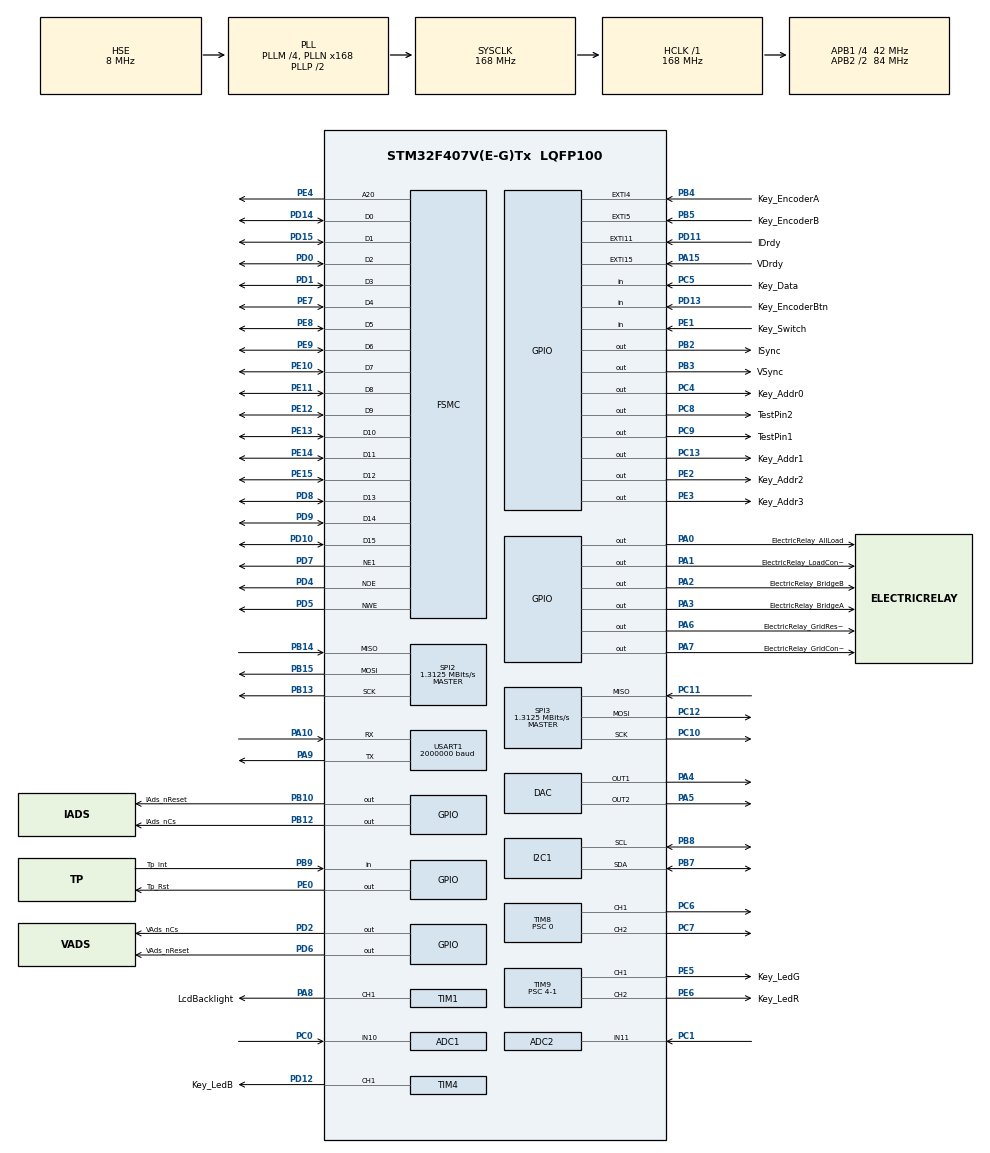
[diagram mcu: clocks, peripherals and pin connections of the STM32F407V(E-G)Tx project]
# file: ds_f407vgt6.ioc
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ADC1.Channel-5\#ChannelRegularConversion=ADC_CHANNEL_10
ADC1.ClockPrescaler=ADC_CLOCK_SYNC_PCLK_DIV8
ADC1.ContinuousConvMode=DISABLE
ADC1.DMAContinuousRequests=ENABLE
ADC1.EOCSelection=ADC_EOC_SEQ_CONV
ADC1.ExternalTrigConv=ADC_EXTERNALTRIGCONV_T2_TRGO
ADC1.NbrOfConversion=1
ADC1.NbrOfConversionFlag=1
ADC1.Rank-5\#ChannelRegularConversion=1
ADC1.SamplingTime-5\#ChannelRegularConversion=ADC_SAMPLETIME_480CYCLES
ADC1.ScanConvMode=DISABLE
ADC1.master=1
ADC2.Channel-1\#ChannelRegularConversion=ADC_CHANNEL_11
ADC2.ClockPrescaler=ADC_CLOCK_SYNC_PCLK_DIV8
ADC2.ContinuousConvMode=DISABLE
ADC2.DMAContinuousRequests=ENABLE
ADC2.EOCSelection=ADC_EOC_SEQ_CONV
ADC2.ExternalTrigConv=ADC_EXTERNALTRIGCONV_T2_TRGO
ADC2.NbrOfConversionFlag=1
ADC2.Rank-1\#ChannelRegularConversion=1
ADC2.SamplingTime-1\#ChannelRegularConversion=ADC_SAMPLETIME_480CYCLES
DAC.DAC_OutputBuffer=DAC_OUTPUTBUFFER_DISABLE
DAC.DAC_OutputBuffer2=DAC_OUTPUTBUFFER_DISABLE
Dma.ADC1.7.Direction=DMA_PERIPH_TO_MEMORY
Dma.ADC1.7.FIFOMode=DMA_FIFOMODE_DISABLE
Dma.ADC1.7.Instance=DMA2_Stream4
Dma.ADC1.7.MemDataAlignment=DMA_MDATAALIGN_HALFWORD
Dma.ADC1.7.MemInc=DMA_MINC_ENABLE
Dma.ADC1.7.Mode=DMA_CIRCULAR
Dma.ADC1.7.PeriphDataAlignment=DMA_PDATAALIGN_HALFWORD
Dma.ADC1.7.PeriphInc=DMA_PINC_DISABLE
Dma.ADC1.7.Priority=DMA_PRIORITY_HIGH
Dma.ADC2.8.Direction=DMA_PERIPH_TO_MEMORY
Dma.ADC2.8.FIFOMode=DMA_FIFOMODE_DISABLE
Dma.ADC2.8.Instance=DMA2_Stream3
Dma.ADC2.8.MemDataAlignment=DMA_MDATAALIGN_HALFWORD
Dma.ADC2.8.MemInc=DMA_MINC_ENABLE
Dma.ADC2.8.Mode=DMA_CIRCULAR
Dma.ADC2.8.PeriphDataAlignment=DMA_PDATAALIGN_HALFWORD
Dma.ADC2.8.PeriphInc=DMA_PINC_DISABLE
Dma.ADC2.8.Priority=DMA_PRIORITY_HIGH
Dma.MEMTOMEM.2.Direction=DMA_MEMORY_TO_MEMORY
Dma.MEMTOMEM.2.FIFOMode=DMA_FIFOMODE_ENABLE
Dma.MEMTOMEM.2.FIFOThreshold=DMA_FIFO_THRESHOLD_FULL
Dma.MEMTOMEM.2.Instance=DMA2_Stream1
Dma.MEMTOMEM.2.MemBurst=DMA_MBURST_SINGLE
Dma.MEMTOMEM.2.MemDataAlignment=DMA_MDATAALIGN_HALFWORD
Dma.MEMTOMEM.2.MemInc=DMA_MINC_DISABLE
Dma.MEMTOMEM.2.Mode=DMA_NORMAL
Dma.MEMTOMEM.2.PeriphBurst=DMA_PBURST_SINGLE
Dma.MEMTOMEM.2.PeriphDataAlignment=DMA_PDATAALIGN_HALFWORD
Dma.MEMTOMEM.2.PeriphInc=DMA_PINC_ENABLE
Dma.MEMTOMEM.2.Priority=DMA_PRIORITY_LOW
Dma.Request0=USART1_RX
Dma.Request1=USART1_TX
Dma.Request2=MEMTOMEM
Dma.Request3=SPI2_RX
Dma.Request4=SPI3_RX
Dma.Request5=SPI2_TX
Dma.Request6=SPI3_TX
Dma.Request7=ADC1
Dma.Request8=ADC2
Dma.SPI2_RX.3.Direction=DMA_PERIPH_TO_MEMORY
Dma.SPI2_RX.3.FIFOMode=DMA_FIFOMODE_DISABLE
Dma.SPI2_RX.3.Instance=DMA1_Stream3
Dma.SPI2_RX.3.MemDataAlignment=DMA_MDATAALIGN_BYTE
Dma.SPI2_RX.3.MemInc=DMA_MINC_ENABLE
Dma.SPI2_RX.3.Mode=DMA_NORMAL
Dma.SPI2_RX.3.PeriphDataAlignment=DMA_PDATAALIGN_BYTE
Dma.SPI2_RX.3.PeriphInc=DMA_PINC_DISABLE
Dma.SPI2_RX.3.Priority=DMA_PRIORITY_LOW
Dma.SPI2_TX.5.Direction=DMA_MEMORY_TO_PERIPH
Dma.SPI2_TX.5.FIFOMode=DMA_FIFOMODE_DISABLE
Dma.SPI2_TX.5.Instance=DMA1_Stream4
Dma.SPI2_TX.5.MemDataAlignment=DMA_MDATAALIGN_BYTE
Dma.SPI2_TX.5.MemInc=DMA_MINC_ENABLE
Dma.SPI2_TX.5.Mode=DMA_NORMAL
Dma.SPI2_TX.5.PeriphDataAlignment=DMA_PDATAALIGN_BYTE
Dma.SPI2_TX.5.PeriphInc=DMA_PINC_DISABLE
Dma.SPI2_TX.5.Priority=DMA_PRIORITY_LOW
Dma.SPI3_RX.4.Direction=DMA_PERIPH_TO_MEMORY
Dma.SPI3_RX.4.FIFOMode=DMA_FIFOMODE_DISABLE
Dma.SPI3_RX.4.Instance=DMA1_Stream0
Dma.SPI3_RX.4.MemDataAlignment=DMA_MDATAALIGN_BYTE
Dma.SPI3_RX.4.MemInc=DMA_MINC_ENABLE
Dma.SPI3_RX.4.Mode=DMA_NORMAL
Dma.SPI3_RX.4.PeriphDataAlignment=DMA_PDATAALIGN_BYTE
Dma.SPI3_RX.4.PeriphInc=DMA_PINC_DISABLE
Dma.SPI3_RX.4.Priority=DMA_PRIORITY_LOW
Dma.SPI3_TX.6.Direction=DMA_MEMORY_TO_PERIPH
Dma.SPI3_TX.6.FIFOMode=DMA_FIFOMODE_DISABLE
Dma.SPI3_TX.6.Instance=DMA1_Stream5
Dma.SPI3_TX.6.MemDataAlignment=DMA_MDATAALIGN_BYTE
Dma.SPI3_TX.6.MemInc=DMA_MINC_ENABLE
Dma.SPI3_TX.6.Mode=DMA_NORMAL
Dma.SPI3_TX.6.PeriphDataAlignment=DMA_PDATAALIGN_BYTE
Dma.SPI3_TX.6.PeriphInc=DMA_PINC_DISABLE
Dma.SPI3_TX.6.Priority=DMA_PRIORITY_LOW
Dma.USART1_RX.0.Direction=DMA_PERIPH_TO_MEMORY
Dma.USART1_RX.0.FIFOMode=DMA_FIFOMODE_DISABLE
Dma.USART1_RX.0.Instance=DMA2_Stream2
Dma.USART1_RX.0.MemDataAlignment=DMA_MDATAALIGN_BYTE
Dma.USART1_RX.0.MemInc=DMA_MINC_ENABLE
Dma.USART1_RX.0.Mode=DMA_NORMAL
Dma.USART1_RX.0.PeriphDataAlignment=DMA_PDATAALIGN_BYTE
Dma.USART1_RX.0.PeriphInc=DMA_PINC_DISABLE
Dma.USART1_RX.0.Priority=DMA_PRIORITY_MEDIUM
Dma.USART1_TX.1.Direction=DMA_MEMORY_TO_PERIPH
Dma.USART1_TX.1.FIFOMode=DMA_FIFOMODE_DISABLE
Dma.USART1_TX.1.Instance=DMA2_Stream7
Dma.USART1_TX.1.MemDataAlignment=DMA_MDATAALIGN_BYTE
Dma.USART1_TX.1.MemInc=DMA_MINC_ENABLE
Dma.USART1_TX.1.Mode=DMA_NORMAL
Dma.USART1_TX.1.PeriphDataAlignment=DMA_PDATAALIGN_BYTE
Dma.USART1_TX.1.PeriphInc=DMA_PINC_DISABLE
Dma.USART1_TX.1.Priority=DMA_PRIORITY_MEDIUM
FREERTOS.INCLUDE_vTaskDelayUntil=1
FREERTOS.Tasks01=defaultTask,0,512,StartDefaultTask,As weak,NULL,Dynamic,NULL,NULL
FREERTOS.configCHECK_FOR_STACK_OVERFLOW=2
FREERTOS.configENABLE_FPU=1
FREERTOS.configGENERATE_RUN_TIME_STATS=1
FREERTOS.configMAX_TASK_NAME_LEN=32
FREERTOS.configRECORD_STACK_HIGH_ADDRESS=1
FREERTOS.configTOTAL_HEAP_SIZE=65536
FREERTOS.configUSE_COUNTING_SEMAPHORES=1
FREERTOS.configUSE_NEWLIB_REENTRANT=1
FREERTOS.configUSE_RECURSIVE_MUTEXES=1
FSMC.AddressSetupTime1=0
FSMC.BusTurnAroundDuration1=0
FSMC.DataSetupTime1=80
FSMC.ExtendedAddressSetupTime1=0
FSMC.ExtendedBusTurnAroundDuration1=0
FSMC.ExtendedDataSetupTime1=11
FSMC.ExtendedMode1=FSMC_EXTENDED_MODE_ENABLE
I2C1.I2C_Mode=I2C_Fast
Mcu.Family=STM32F4
Mcu.Name=STM32F407V(E-G)Tx
Mcu.Package=LQFP100
NVIC.DMA1_Stream0_IRQn=true\:6\:0\:true\:false\:true\:true\:false\:true\:true
NVIC.DMA1_Stream3_IRQn=true\:6\:0\:true\:false\:true\:true\:false\:true\:true
NVIC.DMA1_Stream4_IRQn=true\:6\:0\:true\:false\:true\:true\:false\:true\:true
NVIC.DMA1_Stream5_IRQn=true\:6\:0\:true\:false\:true\:true\:false\:true\:true
NVIC.DMA2_Stream1_IRQn=true\:10\:0\:true\:false\:true\:true\:true\:true\:true
NVIC.DMA2_Stream2_IRQn=true\:10\:0\:true\:false\:true\:true\:true\:true\:true
NVIC.DMA2_Stream3_IRQn=true\:5\:0\:false\:false\:true\:true\:false\:true\:true
NVIC.DMA2_Stream4_IRQn=true\:10\:0\:true\:false\:true\:true\:false\:true\:true
NVIC.DMA2_Stream7_IRQn=true\:10\:0\:true\:false\:true\:true\:true\:true\:true
NVIC.EXTI15_10_IRQn=true\:6\:0\:true\:false\:true\:true\:true\:true\:true
NVIC.EXTI4_IRQn=true\:9\:0\:true\:false\:true\:true\:true\:true\:true
NVIC.EXTI9_5_IRQn=true\:9\:0\:true\:false\:true\:true\:true\:true\:true
NVIC.PriorityGroup=NVIC_PRIORITYGROUP_4
NVIC.TIM2_IRQn=true\:13\:0\:true\:false\:true\:true\:true\:true\:true
NVIC.TIM6_DAC_IRQn=true\:13\:0\:true\:false\:true\:true\:true\:true\:true
NVIC.TIM7_IRQn=true\:0\:0\:true\:false\:true\:false\:false\:true\:true
NVIC.TimeBase=TIM7_IRQn
NVIC.TimeBaseIP=TIM7
NVIC.USART1_IRQn=true\:10\:0\:true\:false\:true\:true\:true\:true\:true
PA0-WKUP.GPIO_Label=ElectricRelay_AllLoad
PA0-WKUP.GPIO_PuPd=GPIO_NOPULL
PA0-WKUP.Signal=GPIO_Output
PA1.GPIO_Label=ElectricRelay_LoadConnector
PA1.GPIO_PuPd=GPIO_NOPULL
PA1.Signal=GPIO_Output
PA10.GPIO_PuPd=GPIO_PULLUP
PA10.Mode=Asynchronous
PA10.Signal=USART1_RX
PA13.Mode=Serial_Wire
PA13.Signal=SYS_JTMS-SWDIO
PA14.Mode=Serial_Wire
PA14.Signal=SYS_JTCK-SWCLK
PA15.GPIO_Label=VDrdy
PA15.GPIO_ModeDefaultEXTI=GPIO_MODE_IT_FALLING
PA15.GPIO_PuPd=GPIO_PULLUP
PA15.Signal=GPXTI15
PA2.GPIO_Label=ElectricRelay_BridgeB
PA2.Signal=GPIO_Output
PA3.GPIO_Label=ElectricRelay_BridgeA
PA3.Signal=GPIO_Output
PA4.Signal=COMP_DAC1_group
PA5.Signal=COMP_DAC2_group
PA6.GPIO_Label=ElectricRelay_GridResisterShorter
PA6.GPIO_PuPd=GPIO_NOPULL
PA6.Signal=GPIO_Output
PA7.GPIO_Label=ElectricRelay_GridConnector
PA7.Signal=GPIO_Output
PA8.GPIO_Label=LcdBacklight
PA8.Signal=S_TIM1_CH1
PA9.GPIO_PuPd=GPIO_PULLUP
PA9.Mode=Asynchronous
PA9.Signal=USART1_TX
PB10.GPIO_Label=IAds_nReset
PB10.GPIO_ModeDefaultOutputPP=GPIO_MODE_OUTPUT_PP
PB10.GPIO_PuPd=GPIO_PULLUP
PB10.PinState=GPIO_PIN_SET
PB10.Signal=GPIO_Output
PB12.GPIO_Label=IAds_nCs
PB12.GPIO_ModeDefaultOutputPP=GPIO_MODE_OUTPUT_PP
PB12.GPIO_PuPd=GPIO_PULLUP
PB12.PinState=GPIO_PIN_SET
PB12.Signal=GPIO_Output
PB13.GPIO_PuPd=GPIO_PULLDOWN
PB13.Mode=Full_Duplex_Master
PB13.Signal=SPI2_SCK
PB14.GPIO_PuPd=GPIO_PULLDOWN
PB14.Mode=Full_Duplex_Master
PB14.Signal=SPI2_MISO
PB15.GPIO_PuPd=GPIO_PULLDOWN
PB15.Mode=Full_Duplex_Master
PB15.Signal=SPI2_MOSI
PB2.GPIO_Label=ISync
PB2.GPIO_PuPd=GPIO_PULLUP
PB2.GPIO_Speed=GPIO_SPEED_FREQ_MEDIUM
PB2.PinState=GPIO_PIN_SET
PB2.Signal=GPIO_Output
PB3.GPIO_Label=VSync
PB3.GPIO_PuPd=GPIO_PULLUP
PB3.GPIO_Speed=GPIO_SPEED_FREQ_MEDIUM
PB3.PinState=GPIO_PIN_SET
PB3.Signal=GPIO_Output
PB4.GPIO_Label=Key_EncoderA
PB4.GPIO_ModeDefaultEXTI=GPIO_MODE_IT_RISING_FALLING
PB4.GPIO_PuPd=GPIO_PULLUP
PB4.Signal=GPXTI4
PB5.GPIO_Label=Key_EncoderB
PB5.GPIO_ModeDefaultEXTI=GPIO_MODE_IT_RISING_FALLING
PB5.GPIO_PuPd=GPIO_PULLUP
PB5.Signal=GPXTI5
PB7.Mode=I2C
PB7.Signal=I2C1_SDA
PB8.Mode=I2C
PB8.Signal=I2C1_SCL
PB9.GPIO_Label=Tp_Int
PB9.Signal=GPIO_Input
PC0.Signal=ADCx_IN10
PC1.Signal=ADCx_IN11
PC10.GPIO_PuPd=GPIO_PULLDOWN
PC10.Mode=Full_Duplex_Master
PC10.Signal=SPI3_SCK
PC11.GPIO_PuPd=GPIO_PULLDOWN
PC11.Mode=Full_Duplex_Master
PC11.Signal=SPI3_MISO
PC12.GPIO_PuPd=GPIO_PULLDOWN
PC12.Mode=Full_Duplex_Master
PC12.Signal=SPI3_MOSI
PC13-ANTI_TAMP.GPIO_Label=Key_Addr1
PC13-ANTI_TAMP.Signal=GPIO_Output
PC4.GPIO_Label=Key_Addr0
PC4.Signal=GPIO_Output
PC5.GPIO_Label=Key_Data
PC5.GPIO_PuPd=GPIO_PULLDOWN
PC5.Signal=GPIO_Input
PC6.Signal=S_TIM8_CH1
PC7.Signal=S_TIM8_CH2
PC8.GPIO_Label=TestPin2
PC8.Signal=GPIO_Output
PC9.GPIO_Label=TestPin1
PC9.Signal=GPIO_Output
PD0.Mode=16b-d1
PD0.Signal=FSMC_D2
PD1.Mode=16b-d1
PD1.Signal=FSMC_D3
PD10.Mode=16b-d1
PD10.Signal=FSMC_D15
PD11.GPIO_Label=IDrdy
PD11.GPIO_ModeDefaultEXTI=GPIO_MODE_IT_FALLING
PD11.GPIO_PuPd=GPIO_PULLUP
PD11.Signal=GPXTI11
PD12.GPIO_Label=Key_LedB
PD12.GPIO_ModeDefaultPP=GPIO_MODE_AF_OD
PD12.Signal=S_TIM4_CH1
PD13.GPIO_Label=Key_EncoderBtn
PD13.GPIO_PuPd=GPIO_PULLUP
PD13.Signal=GPIO_Input
PD14.Mode=16b-d1
PD14.Signal=FSMC_D0
PD15.Mode=16b-d1
PD15.Signal=FSMC_D1
PD2.GPIO_Label=VAds_nCs
PD2.GPIO_PuPd=GPIO_PULLUP
PD2.PinState=GPIO_PIN_SET
PD2.Signal=GPIO_Output
PD4.Mode=Lcd1
PD4.Signal=FSMC_NOE
PD5.Mode=Lcd1
PD5.Signal=FSMC_NWE
PD6.GPIO_Label=VAds_nReset
PD6.GPIO_PuPd=GPIO_PULLUP
PD6.PinState=GPIO_PIN_SET
PD6.Signal=GPIO_Output
PD7.Mode=NorPsramChipSelect1_1
PD7.Signal=FSMC_NE1
PD8.Mode=16b-d1
PD8.Signal=FSMC_D13
PD9.Mode=16b-d1
PD9.Signal=FSMC_D14
PE0.GPIO_Label=Tp_Rst
PE0.Signal=GPIO_Output
PE1.GPIO_Label=Key_Switch
PE1.GPIO_PuPd=GPIO_PULLUP
PE1.Signal=GPIO_Input
PE10.Mode=16b-d1
PE10.Signal=FSMC_D7
PE11.Mode=16b-d1
PE11.Signal=FSMC_D8
PE12.Mode=16b-d1
PE12.Signal=FSMC_D9
PE13.Mode=16b-d1
PE13.Signal=FSMC_D10
PE14.Mode=16b-d1
PE14.Signal=FSMC_D11
PE15.Mode=16b-d1
PE15.Signal=FSMC_D12
PE2.GPIO_Label=Key_Addr2
PE2.Signal=GPIO_Output
PE3.GPIO_Label=Key_Addr3
PE3.Signal=GPIO_Output
PE4.Mode=A20_1
PE4.Signal=FSMC_A20
PE5.GPIO_Label=Key_LedG
PE5.GPIO_ModeDefaultPP=GPIO_MODE_AF_OD
PE5.Signal=S_TIM9_CH1
PE6.GPIO_Label=Key_LedR
PE6.GPIO_ModeDefaultPP=GPIO_MODE_AF_OD
PE6.Signal=S_TIM9_CH2
PE7.Mode=16b-d1
PE7.Signal=FSMC_D4
PE8.Mode=16b-d1
PE8.Signal=FSMC_D5
PE9.Mode=16b-d1
PE9.Signal=FSMC_D6
PH0-OSC_IN.Mode=HSE-External-Oscillator
PH0-OSC_IN.Signal=RCC_OSC_IN
PH1-OSC_OUT.Mode=HSE-External-Oscillator
PH1-OSC_OUT.Signal=RCC_OSC_OUT
ProjectManager.HeapSize=0x200
ProjectManager.StackSize=0x400
ProjectManager.TargetToolchain=STM32CubeIDE
RCC.48MHZClocksFreq_Value=84000000
RCC.AHBFreq_Value=168000000
RCC.APB1CLKDivider=RCC_HCLK_DIV4
RCC.APB1Freq_Value=42000000
RCC.APB1TimFreq_Value=84000000
RCC.APB2CLKDivider=RCC_HCLK_DIV2
RCC.APB2Freq_Value=84000000
RCC.APB2TimFreq_Value=168000000
RCC.CortexFreq_Value=168000000
RCC.HCLKFreq_Value=168000000
RCC.HSE_VALUE=8000000
RCC.HSI_VALUE=16000000
RCC.LSE_VALUE=32768
RCC.PLLM=4
RCC.PLLN=168
RCC.PLLSourceVirtual=RCC_PLLSOURCE_HSE
RCC.SYSCLKFreq_VALUE=168000000
RCC.SYSCLKSource=RCC_SYSCLKSOURCE_PLLCLK
RCC.VCOOutputFreq_Value=336000000
SH.ADCx_IN10.0=ADC1_IN10,IN10
SH.ADCx_IN11.0=ADC2_IN11,IN11
SH.COMP_DAC1_group.0=DAC_OUT1,DAC_OUT1
SH.COMP_DAC2_group.0=DAC_OUT2,DAC_OUT2
SH.S_TIM1_CH1.0=TIM1_CH1,PWM Generation1 CH1
SH.S_TIM4_CH1.0=TIM4_CH1,PWM Generation1 CH1
SH.S_TIM8_CH1.0=TIM8_CH1,PWM Generation1 CH1
SH.S_TIM8_CH2.0=TIM8_CH2,PWM Generation2 CH2
SH.S_TIM9_CH1.0=TIM9_CH1,PWM Generation1 CH1
SH.S_TIM9_CH2.0=TIM9_CH2,PWM Generation2 CH2
SPI2.BaudRatePrescaler=SPI_BAUDRATEPRESCALER_32
SPI2.CLKPhase=SPI_PHASE_2EDGE
SPI2.CalculateBaudRate=1.3125 MBits/s
SPI2.Direction=SPI_DIRECTION_2LINES
SPI2.Mode=SPI_MODE_MASTER
SPI2.VirtualType=VM_MASTER
SPI3.BaudRatePrescaler=SPI_BAUDRATEPRESCALER_32
SPI3.CLKPhase=SPI_PHASE_2EDGE
SPI3.CalculateBaudRate=1.3125 MBits/s
SPI3.Direction=SPI_DIRECTION_2LINES
SPI3.Mode=SPI_MODE_MASTER
SPI3.VirtualType=VM_MASTER
STMicroelectronics.X-CUBE-ALGOBUILD.1.3.0.LibraryCcDSPOoLibraryJjDSPOoLibrary=true
TIM1.AutoReloadPreload=TIM_AUTORELOAD_PRELOAD_ENABLE
TIM1.Channel-PWM\ Generation1\ CH1=TIM_CHANNEL_1
TIM1.Period=999
TIM1.Prescaler=83
TIM1.Pulse-PWM\ Generation1\ CH1=499
TIM2.AutoReloadPreload=TIM_AUTORELOAD_PRELOAD_ENABLE
TIM2.Period=199
TIM2.Prescaler=84-1
TIM2.TIM_MasterOutputTrigger=TIM_TRGO_UPDATE
TIM4.AutoReloadPreload=TIM_AUTORELOAD_PRELOAD_ENABLE
TIM4.Channel-PWM\ Generation1\ CH1=TIM_CHANNEL_1
TIM4.OCPolarity_1=TIM_OCPOLARITY_LOW
TIM4.Period=42000
TIM4.Prescaler=2-1
TIM4.Pulse-PWM\ Generation1\ CH1=0
TIM8.AutoReloadPreload=TIM_AUTORELOAD_PRELOAD_ENABLE
TIM8.Channel-PWM\ Generation1\ CH1=TIM_CHANNEL_1
TIM8.Channel-PWM\ Generation2\ CH2=TIM_CHANNEL_2
TIM8.CounterMode=TIM_COUNTERMODE_CENTERALIGNED1
TIM8.Period=7000
TIM8.Prescaler=0
TIM8.TIM_MasterOutputTrigger=TIM_TRGO_UPDATE
TIM9.AutoReloadPreload=TIM_AUTORELOAD_PRELOAD_ENABLE
TIM9.Channel-PWM\ Generation1\ CH1=TIM_CHANNEL_1
TIM9.Channel-PWM\ Generation2\ CH2=TIM_CHANNEL_2
TIM9.OCPolarity_1=TIM_OCPOLARITY_LOW
TIM9.OCPolarity_2=TIM_OCPOLARITY_LOW
TIM9.Period=42000
TIM9.Prescaler=4-1
TIM9.Pulse-PWM\ Generation1\ CH1=0
TIM9.Pulse-PWM\ Generation2\ CH2=0
USART1.BaudRate=2000000
USART1.VirtualMode=VM_ASYNC
VP_FREERTOS_VS_CMSIS_V1.Mode=CMSIS_V1
VP_STMicroelectronics.X-CUBE-ALGOBUILD_VS_DSPOoLibraryJjLibrary_1.3.0_1.3.0.Mode=DSPOoLibraryJjLibrary
VP_SYS_VS_tim7.Mode=TIM7
VP_TIM1_VS_ClockSourceINT.Mode=Internal
VP_TIM2_VS_ClockSourceINT.Mode=Internal
VP_TIM4_VS_ClockSourceINT.Mode=Internal
VP_TIM8_VS_ClockSourceINT.Mode=Internal
VP_TIM9_VS_ClockSourceINT.Mode=Internal
board=custom

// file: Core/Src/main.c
/* USER CODE BEGIN Header */
/**
  ******************************************************************************
  * @file           : main.c
  * @brief          : Main program body
  ******************************************************************************
  * @attention
  *
  * Copyright (c) 2023 STMicroelectronics.
  * All rights reserved.
  *
  * This software is licensed under terms that can be found in the LICENSE file
  * in the root directory of this software component.
  * If no LICENSE file comes with this software, it is provided AS-IS.
  *
  ******************************************************************************
  */
/* USER CODE END Header */
#include "main.h"
#include "cmsis_os.h"
#include "adc.h"
#include "dac.h"
#include "dma.h"
#include "i2c.h"
#include "spi.h"
#include "tim.h"
#include "usart.h"
#include "gpio.h"
#include "fsmc.h"

/* USER CODE BEGIN Includes */
#include "usercode_vc/User_VC.h"
/* USER CODE END Includes */

void SystemClock_Config(void);
void MX_FREERTOS_Init(void);

int main(void)
{

  /* MCU Configuration--------------------------------------------------------*/

  /* Reset of all peripherals, Initializes the Flash interface and the Systick. */
  HAL_Init();

  /* Configure the system clock */
  SystemClock_Config();

  /* Initialize all configured peripherals */
  MX_GPIO_Init();
  MX_DMA_Init();
  MX_ADC1_Init();
  MX_USART1_UART_Init();
  MX_FSMC_Init();
  MX_TIM1_Init();
  MX_SPI2_Init();
  MX_SPI3_Init();
  MX_TIM8_Init();
  MX_DAC_Init();
  MX_I2C1_Init();
  MX_TIM4_Init();
  MX_TIM9_Init();
  MX_ADC2_Init();
  MX_TIM2_Init();

  /* Call init function for freertos objects (in freertos.c) */
  MX_FREERTOS_Init();

  /* Start scheduler */
  osKernelStart();
  /* We should never get here as control is now taken by the scheduler */
  /* Infinite loop */
  while (1)
  {

  }
}

void SystemClock_Config(void)
{
  RCC_OscInitTypeDef RCC_OscInitStruct = {0};
  RCC_ClkInitTypeDef RCC_ClkInitStruct = {0};

  /** Configure the main internal regulator output voltage
  */
  __HAL_RCC_PWR_CLK_ENABLE();
  __HAL_PWR_VOLTAGESCALING_CONFIG(PWR_REGULATOR_VOLTAGE_SCALE1);

  /** Initializes the RCC Oscillators according to the specified parameters
  * in the RCC_OscInitTypeDef structure.
  */
  RCC_OscInitStruct.OscillatorType = RCC_OSCILLATORTYPE_HSE;
  RCC_OscInitStruct.HSEState = RCC_HSE_ON;
  RCC_OscInitStruct.PLL.PLLState = RCC_PLL_ON;
  RCC_OscInitStruct.PLL.PLLSource = RCC_PLLSOURCE_HSE;
  RCC_OscInitStruct.PLL.PLLM = 4;
  RCC_OscInitStruct.PLL.PLLN = 168;
  RCC_OscInitStruct.PLL.PLLP = RCC_PLLP_DIV2;
  RCC_OscInitStruct.PLL.PLLQ = 4;
  if (HAL_RCC_OscConfig(&RCC_OscInitStruct) != HAL_OK)
  {
    Error_Handler();
  }

  /** Initializes the CPU, AHB and APB buses clocks
  */
  RCC_ClkInitStruct.ClockType = RCC_CLOCKTYPE_HCLK|RCC_CLOCKTYPE_SYSCLK
                              |RCC_CLOCKTYPE_PCLK1|RCC_CLOCKTYPE_PCLK2;
  RCC_ClkInitStruct.SYSCLKSource = RCC_SYSCLKSOURCE_PLLCLK;
  RCC_ClkInitStruct.AHBCLKDivider = RCC_SYSCLK_DIV1;
  RCC_ClkInitStruct.APB1CLKDivider = RCC_HCLK_DIV4;
  RCC_ClkInitStruct.APB2CLKDivider = RCC_HCLK_DIV2;

  if (HAL_RCC_ClockConfig(&RCC_ClkInitStruct, FLASH_LATENCY_5) != HAL_OK)
  {
    Error_Handler();
  }
}

void HAL_TIM_PeriodElapsedCallback(TIM_HandleTypeDef *htim)
{
  /* USER CODE BEGIN Callback 0 */
  extern void MY_TIM_PeriodElapsedCallback(TIM_HandleTypeDef *htim);
  /* USER CODE END Callback 0 */
  if (htim->Instance == TIM7) {
    HAL_IncTick();
  }
  /* USER CODE BEGIN Callback 1 */
  else
  {
    MY_TIM_PeriodElapsedCallback(htim);
  }
  /* USER CODE END Callback 1 */
}

void Error_Handler(void)
{
  __disable_irq();
  while (1)
  {
  }
}

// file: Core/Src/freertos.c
/* USER CODE BEGIN Header */
/**
  ******************************************************************************
  * File Name          : freertos.c
  * Description        : Code for freertos applications
  ******************************************************************************
  * @attention
  *
  * Copyright (c) 2023 STMicroelectronics.
  * All rights reserved.
  *
  * This software is licensed under terms that can be found in the LICENSE file
  * in the root directory of this software component.
  * If no LICENSE file comes with this software, it is provided AS-IS.
  *
  ******************************************************************************
  */
/* USER CODE END Header */

#include "FreeRTOS.h"
#include "task.h"
#include "main.h"
#include "cmsis_os.h"

osThreadId defaultTaskHandle;

void StartDefaultTask(void const * argument);

void MX_FREERTOS_Init(void); /* (MISRA C 2004 rule 8.1) */

/* GetIdleTaskMemory prototype (linked to static allocation support) */
void vApplicationGetIdleTaskMemory( StaticTask_t **ppxIdleTaskTCBBuffer, StackType_t **ppxIdleTaskStackBuffer, uint32_t *pulIdleTaskStackSize );

/* Hook prototypes */
void configureTimerForRunTimeStats(void);
unsigned long getRunTimeCounterValue(void);
void vApplicationStackOverflowHook(xTaskHandle xTask, signed char *pcTaskName);

/* USER CODE BEGIN 1 */
/* Functions needed when configGENERATE_RUN_TIME_STATS is on */
__weak void configureTimerForRunTimeStats(void)
{

}

__weak unsigned long getRunTimeCounterValue(void)
{
return 0;
}
/* USER CODE END 1 */

/* USER CODE BEGIN 4 */
__weak void vApplicationStackOverflowHook(xTaskHandle xTask, signed char *pcTaskName)
{
   /* Run time stack overflow checking is performed if
   configCHECK_FOR_STACK_OVERFLOW is defined to 1 or 2. This hook function is
   called if a stack overflow is detected. */
}
/* USER CODE END 4 */

/* USER CODE BEGIN GET_IDLE_TASK_MEMORY */
static StaticTask_t xIdleTaskTCBBuffer;
static StackType_t xIdleStack[configMINIMAL_STACK_SIZE];

void vApplicationGetIdleTaskMemory( StaticTask_t **ppxIdleTaskTCBBuffer, StackType_t **ppxIdleTaskStackBuffer, uint32_t *pulIdleTaskStackSize )
{
  *ppxIdleTaskTCBBuffer = &xIdleTaskTCBBuffer;
  *ppxIdleTaskStackBuffer = &xIdleStack[0];
  *pulIdleTaskStackSize = configMINIMAL_STACK_SIZE;
  /* place for user code */
}
/* USER CODE END GET_IDLE_TASK_MEMORY */

void MX_FREERTOS_Init(void) {

  /* Create the thread(s) */
  /* definition and creation of defaultTask */
  osThreadDef(defaultTask, StartDefaultTask, osPriorityNormal, 0, 512);
  defaultTaskHandle = osThreadCreate(osThread(defaultTask), NULL);

}

__weak void StartDefaultTask(void const * argument)
{
  for(;;)
  {
    osDelay(1);
  }
}
